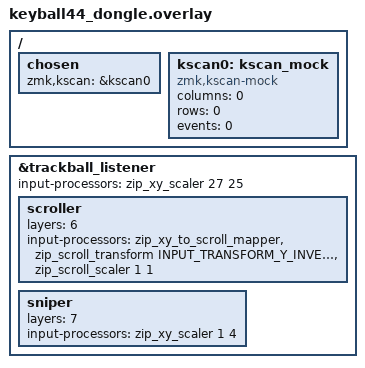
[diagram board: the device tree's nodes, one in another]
/*
 * Keyball44 DONGLE (central).
 *
 * A keyless BLE central: it holds the keymap, connects to both halves as
 * peripherals, and talks to the host over USB/BLE. No key matrix, no display.
 *
 * Trackball: the sensor physically lives on the right half (a peripheral); its
 * motion is forwarded here over BLE via zmk,input-split. We enable the listener
 * and re-implement the old driver-side scroll/snipe (which read the active
 * layer and therefore only work on the central) as layer-gated input-processors.
 */

#include <input/processors.dtsi>
#include <dt-bindings/zmk/input_transform.h>
#include "keyball44_common.dtsi"
#include "keyball44_trackball_split.dtsi"

/ {
    chosen {
        /* Keyless: satisfy ZMK's kscan requirement with a mock scanner. The
         * shared physical-layout also points its kscan at &kscan0 (this mock). */
        zmk,kscan = &kscan0;
    };

    kscan0: kscan_mock {
        compatible = "zmk,kscan-mock";
        columns = <0>;
        rows = <0>;
        events = <0>;
    };
};

/* Receive the forwarded trackball and turn it into pointer HID.
 *
 * Layer 6 = SCROLL, layer 7 = SNIPE (see keyball44.keymap #defines). On those
 * layers the child nodes override the processing:
 *   - SCROLL: map ball X/Y onto the scroll wheel. Smooth scrolling is on
 *     (keyball44_dongle.conf): the host sets a 16x resolution multiplier, so
 *     each unit is 1/16 of a notch -- scaler 1/1 here equals the old 1/16
 *     whole-notch speed. zip_scroll_scaler <1 N>: bigger N == slower.
 *   - SNIPE:  scale pointer X/Y to ~1/4 speed (matches the old 480 vs 1872 CPI
 *     ratio). zip_xy_scaler <1 N>: bigger N == slower/more precise.
 * Orientation/inversion stays in the PMW3610 driver conf on the right half, so
 * events arrive here already corrected.
 */
&trackball_listener {
    status = "okay";

    /* Base pointer speed trim on top of the sensor CPI (1872/4 on the right
     * half). 27/25 = 1.08x (2026-11-13, "bump 5-10%"). Done here rather than
     * via CPI so only the dongle needs re-flashing. zip_xy_scaler tracks
     * remainders, so slow moves don't lose precision. The scroller/sniper
     * children below replace this on their layers, so they are unaffected. */
    input-processors = <&zip_xy_scaler 27 25>;

    scroller {
        layers = <6>;
        /* Y_INVERT: the old driver emitted wheel = -ball_y (INVERT_SCROLL_Y=n
         * still flipped it); the mapper passes ball_y straight through, so
         * vertical scroll came out reversed. Horizontal already matched the
         * old INVERT_SCROLL_X=y behaviour, so it is left alone. */
        input-processors = <&zip_xy_to_scroll_mapper>,
                           <&zip_scroll_transform INPUT_TRANSFORM_Y_INVERT>,
                           <&zip_scroll_scaler 1 1>;
    };

    sniper {
        layers = <7>;
        input-processors = <&zip_xy_scaler 1 4>;
    };
};
